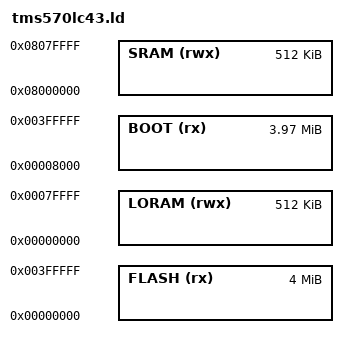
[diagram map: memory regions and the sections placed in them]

/****************************************************************************
 *                                                                          *
 *                         GNAT COMPILER COMPONENTS                         *
 *                                                                          *
 *                                  A R M                                   *
 *                                                                          *
 *                            Linker Script File                            *
 *                                                                          *
 *      Copyright (C) 1999-2002 Universidad Politecnica de Madrid           *
 *             Copyright (C) 2003-2006 The European Space Agency            *
 *                   Copyright (C) 2003-2017 AdaCore                        *
 *                                                                          *
 * GNAT is free software;  you can  redistribute it  and/or modify it under *
 * terms of the  GNU General Public License as published  by the Free Soft- *
 * ware  Foundation;  either version 2,  or (at your option) any later ver- *
 * sion.  GNAT is distributed in the hope that it will be useful, but WITH- *
 * OUT ANY WARRANTY;  without even the  implied warranty of MERCHANTABILITY *
 * or FITNESS FOR A PARTICULAR PURPOSE.  See the GNU General Public License *
 * for  more details.  You should have  received  a copy of the GNU General *
 * Public License  distributed with GNAT;  see file COPYING.  If not, write *
 * to  the  Free Software Foundation,  51  Franklin  Street,  Fifth  Floor, *
 * Boston, MA 02110-1301, USA.                                              *
 *                                                                          *
 * As a  special  exception,  if you  link  this file  with other  files to *
 * produce an executable,  this file does not by itself cause the resulting *
 * executable to be covered by the GNU General Public License. This except- *
 * ion does not  however invalidate  any other reasons  why the  executable *
 * file might be covered by the  GNU Public License.                        *
 *                                                                          *
 * GNARL was developed by the GNARL team at Florida State University.       *
 * Extensive contributions were provided by Ada Core Technologies, Inc.     *
 * The  executive  was developed  by the  Real-Time  Systems  Group  at the *
 * Technical University of Madrid.                                          *
 *                                                                          *
 ****************************************************************************/

/* This is a TMS570 specific version of this file */

/* This linker script defines the FLASH and RAM regions for the TMS570LC43x.
   This also defines the default values for stack size and trap stack size */

MEMORY
{
  /* Default flash mapping */
  FLASH (rx)  : ORIGIN = 0x00000000, LENGTH = 4M
  /* Flash with initial 32K reserved for a boot loader */
  BOOT  (rx)  : ORIGIN = 0x00008000, LENGTH = 4M - 32K
  /* Default SRAM area */
  SRAM  (rwx) : ORIGIN = 0x08000000, LENGTH = 512K
  /* SRAM area mapped at 0x0 */
  LORAM (rwx) : ORIGIN = 0x00000000, LENGTH = 512K
}
